# Polarfire SoC register map
Vendor: Microchip; File version: 1.0
CPU: Microchip PolarFire SoC 1.0, little endian
Registers are 32-bit, read-write, reset 0x0 unless marked. A register's access mark holds for its fields unless they carry their own. Offsets are from the block's base; [hi:lo] are bit positions.

## SPI_A_LO — SPI_A_LO Controller
Base 0x20108000
Same registers: SPI_B_LO 0x20109000, SPI_A_HI 0x28108000, SPI_B_HI 0x28109000
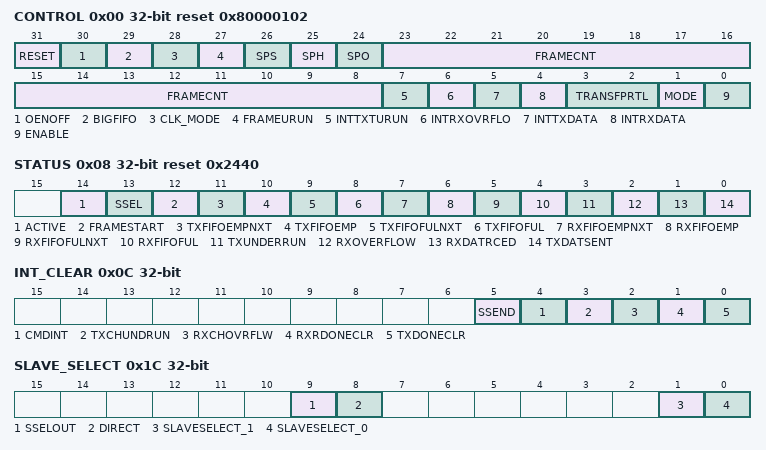
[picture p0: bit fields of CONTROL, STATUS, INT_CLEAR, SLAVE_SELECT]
0x00 CONTROL reset 0x80000102
  [31] RESET — 0: SPI is enabled 1: SPI is held in Power reset state.
  [30] OENOFF — 0: SPI output enable active as required 1: SPI output enable is not asserted. Allows multiple slaves to share a single slave select signal with a single master.
  [29] BIGFIFO — Alters FIFO depth. 0: FIFO depth is 4 frames. 1: when frame size is [4-8] bits: FIFO depth is 32 frames. when frame size is [9-16] bits: FIFO depth is 16; and when frame size is [17-32] bits: FIFO depth is 8.
  [28] CLK_MODE — Specifies the methodology used to calculate the SPICLK divider. 0: SPICLK = 1 / (2 ^ (CLK_GEN + 1)) where CLK_GEN = 0 to 15. 1: SPICLK = 1 / (2 * (CLK_GEN + 1)) where CLK_GEN = 0 to 255
  [27] FRAMEURUN — 0: The under-runs are generated whenever a read is attempted from an empty transmit FIFO. 1: The under-run condition will be ignored for the complete frame.. if the first data frame read resulted in a potential overflow; that is.. the slave was not ready to transmit any data. If the first data frame is read from the FIFO and transmitted.. an under-run will be generated.. when the FIFO becomes empty for any of the remaining packet frames (that is.. while SSEL is active). Master operation does not create a transmit FIFO under-run condition.
  [26] SPS — Defines slave select behavior.
  [25] SPH — Clock phase
  [24] SPO — Clock polarity
  [23:8] FRAMECNT — Number of data frames to be sent or received. Counts from 1. Maximum value is 64K. This register once set will not change, an internal frame counter counts the frames until it reaches the limit set by this register When this register is return, the internal frame counter also reset. When that counter reaches FRAMECNT, interrupts are generated and idle cycles are inserted on the SPI bus. The core will transmit data whenever the transmit FIFO is loaded, the counter is used to count frames, terminate bursts and generate interrupts
  [7] INTTXTURUN — Interrupt on transmit the under-run 0: Interrupt disabled 1: Interrupt enabled
  [6] INTRXOVRFLO — Interrupt on receive overflow 0: Interrupt disable 1: Interrupt enabled
  [5] INTTXDATA — Interrupt on transmit data 0: Interrupt disabled 1: Interrupt enabled
  [4] INTRXDATA — Interrupt on receive data 0: Interrupt disabled 1: Interrupt enabled
  [3:2] TRANSFPRTL — Transfer protocol Decode: 0b00: Motorola SPI 0b01: TI synchronous serial 0b10: National Semiconductor MICROWIRE 0b11: Reserved Note: The transfer protocol cannot be changed while the SPI is enabled.
  [1] MODE — SPI implementation 0: Slave 1: Master (default)
    0=Slave; 1=Master
  [0] ENABLE — Core enable 0: Disable (default) 1: Enable The core will not respond to external signals (SPI_X_DI..SPI_X_DO) until this bit is enabled. SPI_X_CLK is driven low and SPI_X_OEN and SPI_X_SS (slave select) are driven inactive.
0x04 FRAMESIZE reset 0x4 — Transmit and receive data frame size
  [5:0] FRAMESIZE — Transmit and receive data size. Default:4 Maximum value is 32. Number of bits shifted out and received per frame (count starts from 1 to 32). In National Semiconductor MICROWIRE mode.. this is the number of shifts to be done after the control byte is sent. Note: This register must be set before SPI is enabled. Writes to this register are ignored after the SPI is enabled.
0x08 STATUS ro reset 0x2440
  [14] ACTIVE — SPI is still transmitting or receiving data.
  [13] SSEL — Current state of SPI_X_SS[0]
  [12] FRAMESTART — Indicates that the next frame in the receive FIFO was the first received after SSEL went active, i.e. the start of a packet of frames
  [11] TXFIFOEMPNXT — Transmit FIFO will be empty after next transmission
  [10] TXFIFOEMP — Transmit FIFO is empty
  [9] TXFIFOFULNXT — Transmit FIFO full on next write
  [8] TXFIFOFUL — Transmit FIFO is full
  [7] RXFIFOEMPNXT — Receive FIFO empty on next read
  [6] RXFIFOEMP — Receive FIFO empty
  [5] RXFIFOFULNXT — Receive FIFO will be full after next frame received
  [4] RXFIFOFUL — Receive FIFO is full
  [3] TXUNDERRUN — No data available for transmission. The channel cannot read data from the transmit FIFO because the transmit FIFO is empty. Certainly this can only be raised in Slave mode because the master will not attempt to transmit unless there is data in FIFO.
  [2] RXOVERFLOW — Channel is unable to write to receive FIFO as it is full. Applies to Master and Slave modes.
  [1] RXDATRCED — When set.. it indicates that the number of frames specified by TxRXDFCOUNT has been received and can be read. Applies to Master and Slave modes.
  [0] TXDATSENT — When set.. it indicates that the numbers of frames specified by TxRXDFCOUNT has been sent. Applies to Master and Slave modes.
0x0C INT_CLEAR — Interrupt clear register
  [5] SSEND — Write one to clear the interrupt
  [4] CMDINT — Write one to clear the interrupt
  [3] TXCHUNDRUN — Transmit channel under-run
  [2] RXCHOVRFLW — Receive channel over flow
  [1] RXRDONECLR — Clears receive ready (RX_RDY)
  [0] TXDONECLR — Clears transmit done (TX_DONE) by writing '1'
0x10 RX_DATA ro — Receive data register
  [31:0] RXDATA — Received data. Reading this clears the register of the received data.
0x14 TX_DATA ro — Transmit data register
  [31:0] TXDATA rw — Data to be transmitted. Writing to this clears the last data transmitted.
0x18 CLK_GEN reset 0x7 — Output clock generator (Master mode)
  [7:0] CLK_GEN — Specifies the methodology used to calculate the SPICLK divider. CLK_MODE = 0: SPICLK = 1 / (2^(CLK_GEN + 1)) where CLK_GEN = 0 to 15. CLK_MODE = 1: SPICLK = 1 / (2 * (CLK_GEN + 1)) where CLK_GEN = 0 to 255.
0x1C SLAVE_SELECT — Specifies slave selected (Master mode). Writing one to a bit position selects the corresponding slave. One SLAVESELECT[1] is available at the FPGA fabric interface.. while SLAVESELECT[0] is available at the SPI_X_SS[0] pin. Note: The slave select output signal is active low.
  [9] SSELOUT — 0: SSEL is inactive (Driven to 1) 1: SSEL is active (Driven to 0)
  [8] DIRECT — 0: SSEL is driven by the FSM's 1: SSEL is driven by bit 9 in this register
  [1] SLAVESELECT_1 — The slave select output signal is active low.
  [0] SLAVESELECT_0 — The slave select output signal is active low.
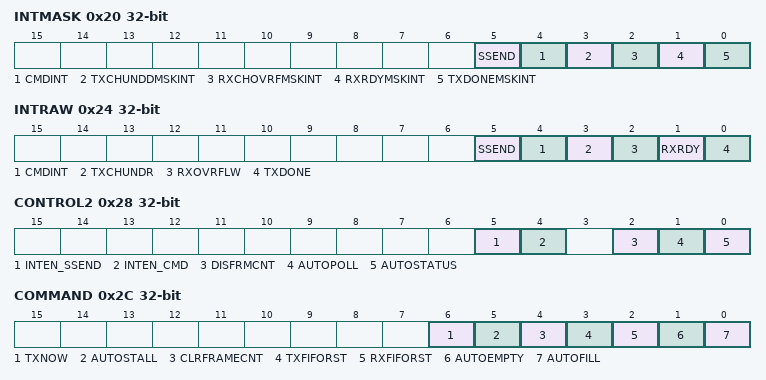
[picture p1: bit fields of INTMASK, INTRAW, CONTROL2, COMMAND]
0x20 INTMASK ro — Masked interrupt status
  [5] SSEND — Equals RIS[5] and CONTROL2[5]. When this is high.. the interrupt is active.
  [4] CMDINT — Equals RIS[4] and CONTROL2[4]. When this is high.. the interrupt is active.
  [3] TXCHUNDDMSKINT — Masked interrupt status. Reading this returns interrupt status. Masked interrupt status = Raw interrupt status and interrupt mask (Control Register). MIS = RIS and CONTROL[7:4]. Masked status of transmit channel under-run TXCHUNDMSKINT=TXCHUNDRINT and INTTXUNRRUN
  [2] RXCHOVRFMSKINT — Masked status of receive channel overflow. RXCHOVRFMSKINT = RXCHOVRFINT and INTRXOVRFLO
  [1] RXRDYMSKINT — Masked status of receive data ready (data received in FIFO). RXRDYMSKINT = RXRDY and INTTXDATA
  [0] TXDONEMSKINT — Masked status of transmit done (data shifted out) TXDONEMSKINT = TXDONE and INTRXDATA
0x24 INTRAW ro — Raw interrupt status
  [5] SSEND — Indicates that SPI_X_SS[x] has gone inactive.
  [4] CMDINT — Indicates that the number of frames set by the CMDSIZE register has been received as a single packet of frames (SPI_X_SS[x] held active).
  [3] TXCHUNDR — RAW interrupt status. Reading this returns raw interrupt status. Raw status of transmit channel under-run. Indicates in slave mode that data was not availiable when required in the transmit FIFO
  [2] RXOVRFLW — Raw status of receive FIFO overflowed
  [1] RXRDY — Receive data ready (data received in FIFO)
  [0] TXDONE — Raw status of transmit done (data shifted out)
0x28 CONTROL2 — Control bits for enhanced modes
  [5] INTEN_SSEND — 0:No effect 1: Enables the interrupt as SPI_X_SS[x] has gone inactive.
  [4] INTEN_CMD — 0: No effect. 1: Enables the interrupt after the number of frames set by the CMDSIZE register have been received as a single packet of frames (SPI_X_SS[x] held active).
  [2] DISFRMCNT — 0: The internal frame counter is active. When the counter reaches the programmed limit.. it will pause the current SPI transfer inserting idle cycles and generate the appropriate interrupts. 1: The internal frame counter is not active.The core transmits data until the transmit FIFO empties. The FRAMECNT (CONTROL register) should also be programmed to zero.
  [1] AUTOPOLL — 0: No effect 1: The first receive frame after SPI_X_SS[0] is active. It is discarded (not written to the FIFO) and supports the POLL function.
  [0] AUTOSTATUS — 0: No effect 1: The first transmitted frame (Slave mode) contains the hardware status.. not data from the transmit FIFO.
0x2C COMMAND
  [6] TXNOW — 0: No effect 1: Writing 1 clears the TxBUSY bit in Slave mode immediately rather than waiting for PKTSIZE frames to be available.. telling the master that there is data available. This is intended to use when less than the programmed PKTSIZE data frames are being transmitted.. removing the requirement to transmit PKTSIZE frames. This bit stays set until the first data frame is transmitted.
  [5] AUTOSTALL — 0: No effect 1: Writing 1 will cause the master to delay transmission until the transmit FIFO contains the number of frames specified by the PKTSIZE register. This guarantee that the frames are transmitted with no idle cycles or time gaps between them. This bit will be automatically cleared as soon as the core starts transmitting the frames.
  [4] CLRFRAMECNT — 0: No effect 1: Writing 1 clears the internal frame counter. This bit always reads as zero. The counter is also cleared when the core is disabled.. CTL1.. or CTL2 are written (that is.. the frame count limit changed).
  [3] TXFIFORST — 0: No effect 1: Writing 1 resets the Tx FIFO. This bit always reads as zero.
  [2] RXFIFORST — 0: No effect Writing 1 resets the Rx FIFO. This bit always reads as zero.
  [1] AUTOEMPTY — 0: No effect 1: Writing 1 causes the SPI core to automatically discard any further received data until the number of frames requested in the FRAMECNT register has been received or (in Slave mode) SSEL goes inactive. This bit will stay set until all the frames are complete or it is cleared.
  [0] AUTOFILL — 0: No effect 1: Writing 1 causes the SPI core to automatically fill the transmit FIFO with zeros to match the number of frames requested in the FRAMECNT register. Typically.. the five command bytes must be written to the TxDATA register and then this bit must be set. Data can be read from the receive FIFO until the complete set of frames has been read. This bit will stay set until all the frames are complete or it is cleared.
0x30 PKTSIZE — Packet size
  [5:0] PKTSIZE — Sets the size of the SPI CMD/data frame. PKTSIZE cannot be greater than the FIFO size.
0x34 CMD_SIZE — Command size
  [5:0] CMDSIZE — Number of frames after SPI_SS[0] going active that the CMD interrupt should be generated. Note: This controls the RxCMD interrupt. The internal counters count frames from SPI_SS[0] going low. It automatically resets and starts counting again once SSEL goes inactive. In TI mode.. back- to-back frames are counted.. any gaps in data causes the counter to start counting again.
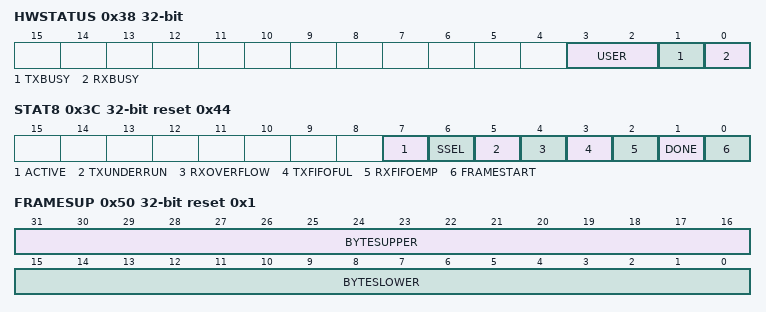
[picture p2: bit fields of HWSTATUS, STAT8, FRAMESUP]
0x38 HWSTATUS — Slave hardware status
  [3:2] USER — These bits are set by the CPU. Their function is undefined but could be used to send additional status or request information to the master.
  [1] TXBUSY ro — 0: Master may request the requested data. There are PKTSIZE frames of data in the transmit FIFO (when AUTOPOLL is set to PKTSIZE - 1) 1: Indicates not ready to transmit data.
  [0] RXBUSY ro — 1: Indicates that the receive buffer is busy (not empty). 0: Indicates that up to PKTSIZE frames of command followed by data may be sent to the slave.
0x3C STAT8 reset 0x44 — Status register
  [7] ACTIVE — SPI is still transmitting the data
  [6] SSEL — Current state of SPI_X_SS[0]
  [5] TXUNDERRUN — Transmit FIFO underflowed
  [4] RXOVERFLOW — Receive FIFO overflowed
  [3] TXFIFOFUL — Transmit FIFO is full
  [2] RXFIFOEMP — Receive FIFO is empty
  [1] DONE — The number of request frames have been transmitted and received.
  [0] FRAMESTART — Next frame in receive FIFO was received after SPI_X_SS[x] went active (command frame).
0x40 CTRL0 reset 0x2
  [7:0] CTRL0 — Aliased CONTROL register bits 7:0. This register allows byte operations from an 8-bit processor in the fabric. It is not intended for access from internal MSS masters.
0x44 CTRL1 reset 0x1
  [7:0] CTRL1 — Aliased CONTROL register bits 15:8. This register allows byte operations from an 8-bit processor in the fabric. It is not intended for access from internal MSS masters.
0x48 CTRL2
  [7:0] CTRL2 — Aliased CONTROL register bits 23:16. This register allows byte operations from an 8-bit processor in the fabric. It is not intended for access from internal MSS masters.
0x4C CTRL3 reset 0x80
  [7:0] CTRL3 — Aliased CONTROL register bits 31:24. This register allows byte operations from an 8-bit processor in the fabric. It is not intended for access from internal MSS masters.
0x50 FRAMESUP reset 0x1
  [31:16] BYTESUPPER — W: Writes the upper 16 bits of the number of bytes to be transmitted. R: Returns the written value.
  [15:0] BYTESLOWER — W: No operation. R: Resturns the lower 16 bits of the byte count from the FRAMES register.
